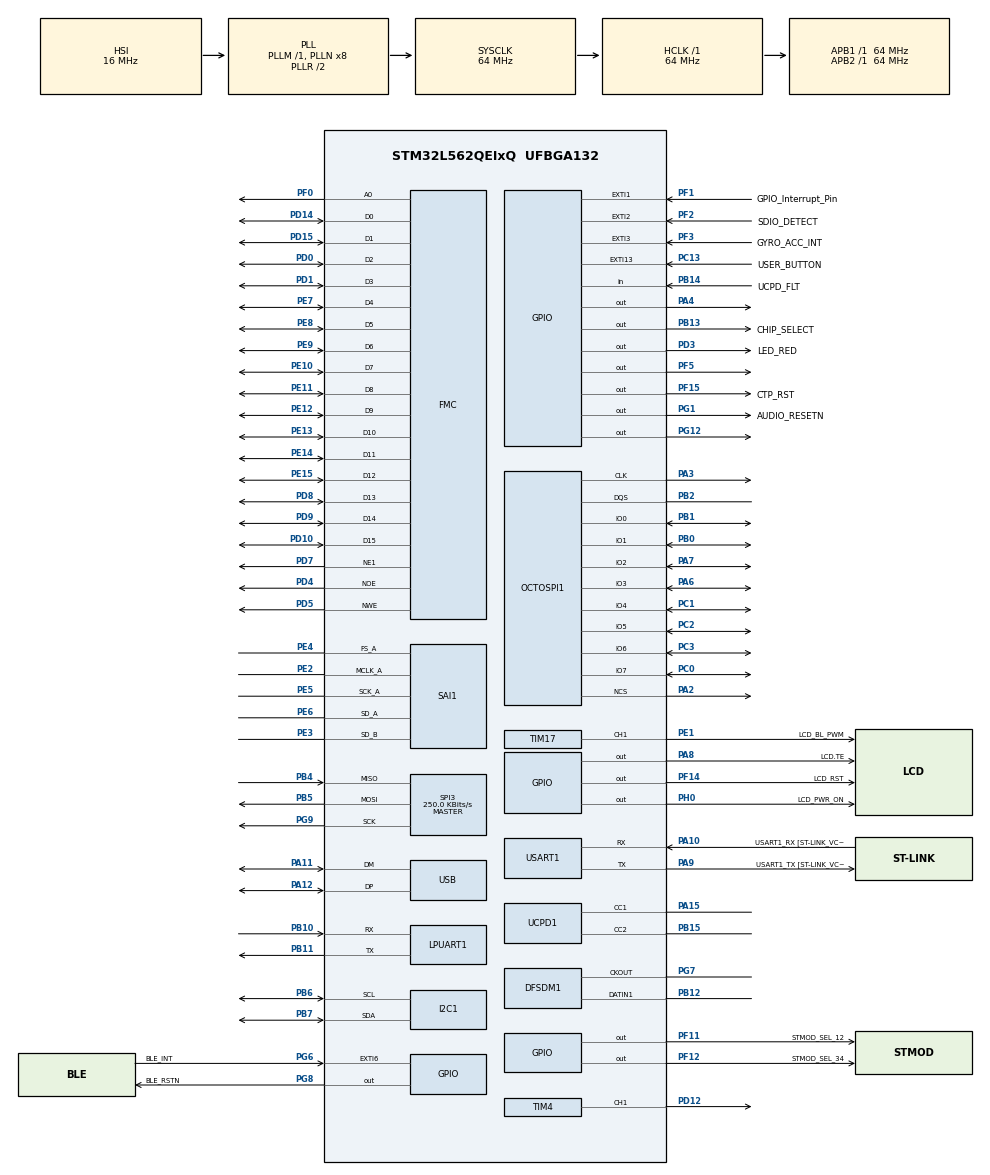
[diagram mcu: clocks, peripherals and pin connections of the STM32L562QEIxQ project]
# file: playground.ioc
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I2C1.Timing=0x10707DBC
Mcu.Family=STM32L5
Mcu.Name=STM32L562QEIxQ
Mcu.Package=UFBGA132
Mcu.TrustZone=disable
NVIC.EXTI13_IRQn=true\:0\:0\:false\:false\:true\:true\:true
NVIC.PriorityGroup=NVIC_PRIORITYGROUP_3
NVIC.TIM4_IRQn=true\:0\:0\:false\:false\:true\:true\:true
PA10.GPIO_Label=USART1_RX [ST-LINK_VCP_TX]
PA10.Mode=Asynchronous
PA10.Signal=USART1_RX
PA11.Mode=Device
PA11.Signal=USB_DM
PA12.Mode=Device
PA12.Signal=USB_DP
PA13\ (JTMS/SWDIO).Mode=Trace_Asynchronous_SW
PA13\ (JTMS/SWDIO).Signal=DEBUG_JTMS-SWDIO
PA14\ (JTCK/SWCLK).Mode=Trace_Asynchronous_SW
PA14\ (JTCK/SWCLK).Signal=DEBUG_JTCK-SWCLK
PA15\ (JTDI).Mode=Source_AllSignals
PA15\ (JTDI).Signal=UCPD1_CC1
PA2.Mode=octods_mode
PA2.Signal=OCTOSPI1_NCS
PA3.Mode=octods_mode
PA3.Signal=OCTOSPI1_CLK
PA4.Signal=GPIO_Output
PA6.Mode=octods_mode
PA6.Signal=OCTOSPI1_IO3
PA7.Mode=octods_mode
PA7.Signal=OCTOSPI1_IO2
PA8.GPIO_Label=LCD.TE
PA8.Signal=GPIO_Output
PA9.GPIO_Label=USART1_TX [ST-LINK_VCP_RX]
PA9.Mode=Asynchronous
PA9.Signal=USART1_TX
PB0.Mode=octods_mode
PB0.Signal=OCTOSPI1_IO1
PB1.Mode=octods_mode
PB1.Signal=OCTOSPI1_IO0
PB10.Mode=Asynchronous
PB10.Signal=LPUART1_RX
PB11.Mode=Asynchronous
PB11.Signal=LPUART1_TX
PB12.Signal=S_DATAIN1DFSDM1
PB13.GPIO_Label=CHIP_SELECT
PB13.Signal=GPIO_Output
PB14.GPIO_Label=UCPD_FLT
PB14.Signal=GPIO_Input
PB15.Mode=Source_AllSignals
PB15.Signal=UCPD1_CC2
PB2.Mode=octods_mode
PB2.Signal=OCTOSPI1_DQS
PB3\ (JTDO/TRACESWO).Mode=Trace_Asynchronous_SW
PB3\ (JTDO/TRACESWO).Signal=DEBUG_JTDO-SWO
PB4\ (NJTRST).Mode=Full_Duplex_Master
PB4\ (NJTRST).Signal=SPI3_MISO
PB5.Mode=Full_Duplex_Master
PB5.Signal=SPI3_MOSI
PB6.Mode=I2C
PB6.Signal=I2C1_SCL
PB7.Mode=I2C
PB7.Signal=I2C1_SDA
PC0.Mode=octods_mode
PC0.Signal=OCTOSPI1_IO7
PC1.Mode=octods_mode
PC1.Signal=OCTOSPI1_IO4
PC10.Signal=SDMMC1_D2
PC11.Signal=SDMMC1_D3
PC12.Signal=SDMMC1_CK
PC13.GPIO_Label=USER_BUTTON
PC13.Signal=GPXTI13
PC14-OSC32_IN\ (PC14).Mode=LSE-External-Oscillator
PC14-OSC32_IN\ (PC14).Signal=RCC_OSC32_IN
PC15-OSC32_OUT\ (PC15).Mode=LSE-External-Oscillator
PC15-OSC32_OUT\ (PC15).Signal=RCC_OSC32_OUT
PC2.Mode=octods_mode
PC2.Signal=OCTOSPI1_IO5
PC3.Mode=octods_mode
PC3.Signal=OCTOSPI1_IO6
PC8.Signal=SDMMC1_D0
PC9.Signal=SDMMC1_D1
PD0.Signal=FMC_D2_DA2
PD1.Signal=FMC_D3_DA3
PD10.Signal=FMC_D15_DA15
PD12.Signal=S_TIM4_CH1
PD14.Signal=FMC_D0_DA0
PD15.Signal=FMC_D1_DA1
PD2.Signal=SDMMC1_CMD
PD3.GPIO_Label=LED_RED
PD3.Signal=GPIO_Output
PD4.Signal=FMC_NOE
PD5.Signal=FMC_NWE
PD7.Mode=NorPsramChipSelect1_1
PD7.Signal=FMC_NE1
PD8.Signal=FMC_D13_DA13
PD9.Signal=FMC_D14_DA14
PE1.GPIO_Label=LCD_BL_PWM
PE1.Signal=S_TIM17_CH1
PE10.Signal=FMC_D7_DA7
PE11.Signal=FMC_D8_DA8
PE12.Signal=FMC_D9_DA9
PE13.Signal=FMC_D10_DA10
PE14.Signal=FMC_D11_DA11
PE15.Signal=FMC_D12_DA12
PE2.Mode=SAI_A_MasterWithClock
PE2.Signal=SAI1_MCLK_A
PE3.Mode=SAI_B_SPDIF
PE3.Signal=SAI1_SD_B
PE4.Mode=SAI_A_MasterWithClock
PE4.Signal=SAI1_FS_A
PE5.Mode=SAI_A_MasterWithClock
PE5.Signal=SAI1_SCK_A
PE6.Mode=SAI_A_MasterWithClock
PE6.Signal=SAI1_SD_A
PE7.Signal=FMC_D4_DA4
PE8.Signal=FMC_D5_DA5
PE9.Signal=FMC_D6_DA6
PF0.Signal=FMC_A0
PF1.GPIO_Label=GPIO_Interrupt_Pin
PF1.Signal=GPXTI1
PF11.GPIO_Label=STMOD_SEL_12
PF11.Signal=GPIO_Output
PF12.GPIO_Label=STMOD_SEL_34
PF12.Signal=GPIO_Output
PF14.GPIO_Label=LCD_RST
PF14.Signal=GPIO_Output
PF15.GPIO_Label=CTP_RST
PF15.Signal=GPIO_Output
PF2.GPIO_Label=SDIO_DETECT
PF2.Signal=GPXTI2
PF3.GPIO_Label=GYRO_ACC_INT
PF3.Signal=GPXTI3
PF5.Signal=GPIO_Output
PG1.GPIO_Label=AUDIO_RESETN
PG1.Signal=GPIO_Output
PG12.Signal=GPIO_Output
PG2.Signal=SPI1_SCK
PG3.Signal=SPI1_MISO
PG4.Signal=SPI1_MOSI
PG5.GPIO_Label=BLE_CSN
PG5.Signal=SPI1_NSS
PG6.GPIO_Label=BLE_INT
PG6.Signal=GPXTI6
PG7.Signal=S_CKOUTDFSDM1
PG8.GPIO_Label=BLE_RSTN
PG8.Signal=GPIO_Output
PG9.Mode=Full_Duplex_Master
PG9.Signal=SPI3_SCK
PH0-OSC_IN\ (PH0).GPIO_Label=LCD_PWR_ON
PH0-OSC_IN\ (PH0).Signal=GPIO_Output
ProjectManager.HeapSize=0x200
ProjectManager.StackSize=0x400
ProjectManager.TargetToolchain=STM32CubeIDE
RCC.ADCFreq_Value=96000000
RCC.AHBFreq_Value=64000000
RCC.APB1Freq_Value=64000000
RCC.APB1TimFreq_Value=64000000
RCC.APB2Freq_Value=64000000
RCC.APB2TimFreq_Value=64000000
RCC.CK48CLockSelection=RCC_USBCLKSOURCE_MSI
RCC.CortexFreq_Value=64000000
RCC.HCLKFreq_Value=64000000
RCC.HSE_VALUE=8000000
RCC.HSI48_VALUE=48000000
RCC.HSI_VALUE=16000000
RCC.MSIClockRange=RCC_MSIRANGE_11
RCC.MSI_VALUE=48000000
RCC.PLLSAI1M=4
RCC.PLLSAI1N=48
RCC.PLLSAI1P=RCC_PLLP_DIV17
RCC.PLLSAI1Source=RCC_PLLSAI1SOURCE_HSI
RCC.PLLSourceVirtual=RCC_PLLSOURCE_HSI
RCC.SDMMCClockSelection=RCC_SDIOCLKSOURCE_CLK48
RCC.SYSCLKFreq_VALUE=64000000
RCC.SYSCLKSource=RCC_SYSCLKSOURCE_PLLCLK
RCC.USBFreq_Value=48000000
RCC.VCOOutputFreq_Value=128000000
SAI1.ErrorAudioFreq-SAI_A_MasterWithClock=-77.02 %
SAI1.Instance-SAI_A_MasterWithClock=SAI$Index_Block_A
SAI1.Instance-SAI_B_SPDIF=SAI$Index_Block_B
SAI1.MckOutput-SAI_A_MasterWithClock=SAI_MCK_OUTPUT_ENABLE
SAI1.RealAudioFreq-SAI_A_MasterWithClock=44.117 KHz
SAI1.RealAudioFreq-SAI_B_SPDIF=214.285 KHz
SAI1.VirtualMode-SAI_A_MasterWithClock=VM_MASTER
SAI1.VirtualMode-SAI_B_SPDIF=VM_SPDIF
SH.FMC_A0.0=FMC_A0,A0_1
SH.FMC_D0_DA0.0=FMC_DA0
SH.FMC_D0_DA0.1=FMC_D0,16b-d1
SH.FMC_D10_DA10.0=FMC_DA10
SH.FMC_D10_DA10.1=FMC_D10,16b-d1
SH.FMC_D11_DA11.0=FMC_DA11
SH.FMC_D11_DA11.1=FMC_D11,16b-d1
SH.FMC_D12_DA12.0=FMC_DA12
SH.FMC_D12_DA12.1=FMC_D12,16b-d1
SH.FMC_D13_DA13.0=FMC_DA13
SH.FMC_D13_DA13.1=FMC_D13,16b-d1
SH.FMC_D14_DA14.0=FMC_DA14
SH.FMC_D14_DA14.1=FMC_D14,16b-d1
SH.FMC_D15_DA15.0=FMC_DA15
SH.FMC_D15_DA15.1=FMC_D15,16b-d1
SH.FMC_D1_DA1.0=FMC_DA1
SH.FMC_D1_DA1.1=FMC_D1,16b-d1
SH.FMC_D2_DA2.0=FMC_DA2
SH.FMC_D2_DA2.1=FMC_D2,16b-d1
SH.FMC_D3_DA3.0=FMC_DA3
SH.FMC_D3_DA3.1=FMC_D3,16b-d1
SH.FMC_D4_DA4.0=FMC_DA4
SH.FMC_D4_DA4.1=FMC_D4,16b-d1
SH.FMC_D5_DA5.0=FMC_DA5
SH.FMC_D5_DA5.1=FMC_D5,16b-d1
SH.FMC_D6_DA6.0=FMC_DA6
SH.FMC_D6_DA6.1=FMC_D6,16b-d1
SH.FMC_D7_DA7.0=FMC_DA7
SH.FMC_D7_DA7.1=FMC_D7,16b-d1
SH.FMC_D8_DA8.0=FMC_DA8
SH.FMC_D8_DA8.1=FMC_D8,16b-d1
SH.FMC_D9_DA9.0=FMC_DA9
SH.FMC_D9_DA9.1=FMC_D9,16b-d1
SH.FMC_NOE.0=FMC_NOE,Lcd1
SH.FMC_NWE.0=FMC_NWE,Lcd1
SH.S_CKOUTDFSDM1.0=DFSDM1_CKOUT,CKOUT
SH.S_DATAIN1DFSDM1.0=DFSDM1_DATIN1,Manchester_input_from_ch1
SH.S_TIM17_CH1.0=TIM17_CH1,PWM Generation1 CH1
SH.S_TIM4_CH1.0=TIM4_CH1,Output Compare1 CH1
SPI3.BaudRatePrescaler=SPI_BAUDRATEPRESCALER_256
SPI3.CalculateBaudRate=250.0 KBits/s
SPI3.DataSize=SPI_DATASIZE_8BIT
SPI3.Direction=SPI_DIRECTION_2LINES
SPI3.FirstBit=SPI_FIRSTBIT_MSB
SPI3.Mode=SPI_MODE_MASTER
SPI3.VirtualType=VM_MASTER
TIM17.Channel=TIM_CHANNEL_1
TIM4.AutoReloadPreload=TIM_AUTORELOAD_PRELOAD_DISABLE
TIM4.Channel-Output\ Compare1\ CH1=TIM_CHANNEL_1
TIM4.OCMode_1=TIM_OCMODE_TOGGLE
TIM4.Period=9999
TIM4.Prescaler=6399
USART1.VirtualMode-Asynchronous=VM_ASYNC
VP_DFSDM1_VS_IN0.Mode=Parallel_Input_ch0
VP_DFSDM1_VS_IN2.Mode=Parallel_Input_ch2
VP_PWR_VS_DBSignals.Mode=DisableDeadBatterySignals
VP_TIM16_VS_ClockSourceINT.Mode=Enable_Timer
VP_TIM17_VS_ClockSourceINT.Mode=Enable_Timer
VP_TIM4_VS_ClockSourceINT.Mode=Internal
board=STM32L562E-DK

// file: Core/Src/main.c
/* USER CODE BEGIN Header */
/**
  ******************************************************************************
  * @file           : main.c
  * @brief          : Main program body
  ******************************************************************************
  * @attention
  *
  * <h2><center>&copy; Copyright (c) 2022 STMicroelectronics.
  * All rights reserved.</center></h2>
  *
  * This software component is licensed by ST under BSD 3-Clause license,
  * the "License"; You may not use this file except in compliance with the
  * License. You may obtain a copy of the License at:
  *                        opensource.org/licenses/BSD-3-Clause
  *
  ******************************************************************************
  */
/* USER CODE END Header */
#include "main.h"
#include "dfsdm.h"
#include "i2c.h"
#include "usart.h"
#include "octospi.h"
#include "sai.h"
#include "spi.h"
#include "tim.h"
#include "ucpd.h"
#include "usb.h"
#include "gpio.h"
#include "fmc.h"

/* USER CODE BEGIN Includes */
#include "lib_radio.h"
/* USER CODE END Includes */

/* USER CODE BEGIN PD */
#define INT_ARRAY_SIZE                          16u
#define TEST_MSG_ARRAY_SIZE                     18u
#define TEST_MSG_TO_SEND                        {0x11, 0xF4, 0xF3, 0xF2, 0xF1, 0x34, 0x33, 0x32, 0x31, 0x80, 0x07, 0xC5, 0xC5, 0xC5, 0xC5, 0xC5, 0xC5, 0xC5}
/* USER CODE END PD */

/* USER CODE BEGIN PV */
uint8_t* IntArrayPtr;
uint8_t IntArray[INT_ARRAY_SIZE];
/* USER CODE END PV */

void SystemClock_Config(void);
void PeriphCommonClock_Config(void);

int main(void)
{

  /* MCU Configuration--------------------------------------------------------*/

  /* Reset of all peripherals, Initializes the Flash interface and the Systick. */
  HAL_Init();

  /* Configure the system clock */
  SystemClock_Config();

/* Configure the peripherals common clocks */
  PeriphCommonClock_Config();

  /* Initialize all configured peripherals */
  MX_GPIO_Init();
  MX_DFSDM1_Init();
  MX_FMC_Init();
  MX_I2C1_Init();
  MX_LPUART1_UART_Init();
  MX_USART1_UART_Init();
  MX_OCTOSPI1_Init();
  MX_SAI1_Init();
  MX_TIM4_Init();
  MX_TIM16_Init();
  MX_TIM17_Init();
  MX_UCPD1_Init();
  MX_USB_PCD_Init();
  MX_SPI3_Init();
  /* USER CODE BEGIN 2 */
  uint8_t TestArrayMessage[TEST_MSG_ARRAY_SIZE] = TEST_MSG_TO_SEND;

  HAL_GPIO_WritePin(STMOD_SEL_12_GPIO_Port, STMOD_SEL_12_Pin, GPIO_PIN_RESET); /* Set SEL pin states to initiate SPI3 on CN4 */
  HAL_GPIO_WritePin(STMOD_SEL_34_GPIO_Port, STMOD_SEL_34_Pin, GPIO_PIN_RESET);

  sendConfigurationSettings(&hspi3, CHIP_SELECT_GPIO_Port, CHIP_SELECT_Pin);
  sendMessage(TestArrayMessage, TEST_MSG_ARRAY_SIZE);
  getRadioIntStatus(IntArray);
  /* USER CODE END 2 */

  /* Infinite loop */
   while (1)
  {

  }
}

void SystemClock_Config(void)
{
  RCC_OscInitTypeDef RCC_OscInitStruct = {0};
  RCC_ClkInitTypeDef RCC_ClkInitStruct = {0};

  /** Configure the main internal regulator output voltage
  */
  if (HAL_PWREx_ControlVoltageScaling(PWR_REGULATOR_VOLTAGE_SCALE1) != HAL_OK)
  {
    Error_Handler();
  }
  /** Configure LSE Drive Capability
  */
  HAL_PWR_EnableBkUpAccess();
  __HAL_RCC_LSEDRIVE_CONFIG(RCC_LSEDRIVE_LOW);
  /** Initializes the RCC Oscillators according to the specified parameters
  * in the RCC_OscInitTypeDef structure.
  */
  RCC_OscInitStruct.OscillatorType = RCC_OSCILLATORTYPE_HSI|RCC_OSCILLATORTYPE_LSE
                              |RCC_OSCILLATORTYPE_MSI;
  RCC_OscInitStruct.LSEState = RCC_LSE_ON;
  RCC_OscInitStruct.HSIState = RCC_HSI_ON;
  RCC_OscInitStruct.HSICalibrationValue = RCC_HSICALIBRATION_DEFAULT;
  RCC_OscInitStruct.MSIState = RCC_MSI_ON;
  RCC_OscInitStruct.MSICalibrationValue = RCC_MSICALIBRATION_DEFAULT;
  RCC_OscInitStruct.MSIClockRange = RCC_MSIRANGE_11;
  RCC_OscInitStruct.PLL.PLLState = RCC_PLL_ON;
  RCC_OscInitStruct.PLL.PLLSource = RCC_PLLSOURCE_HSI;
  RCC_OscInitStruct.PLL.PLLM = 1;
  RCC_OscInitStruct.PLL.PLLN = 8;
  RCC_OscInitStruct.PLL.PLLP = RCC_PLLP_DIV7;
  RCC_OscInitStruct.PLL.PLLQ = RCC_PLLQ_DIV2;
  RCC_OscInitStruct.PLL.PLLR = RCC_PLLR_DIV2;
  if (HAL_RCC_OscConfig(&RCC_OscInitStruct) != HAL_OK)
  {
    Error_Handler();
  }
  /** Initializes the CPU, AHB and APB buses clocks
  */
  RCC_ClkInitStruct.ClockType = RCC_CLOCKTYPE_HCLK|RCC_CLOCKTYPE_SYSCLK
                              |RCC_CLOCKTYPE_PCLK1|RCC_CLOCKTYPE_PCLK2;
  RCC_ClkInitStruct.SYSCLKSource = RCC_SYSCLKSOURCE_PLLCLK;
  RCC_ClkInitStruct.AHBCLKDivider = RCC_SYSCLK_DIV1;
  RCC_ClkInitStruct.APB1CLKDivider = RCC_HCLK_DIV1;
  RCC_ClkInitStruct.APB2CLKDivider = RCC_HCLK_DIV1;

  if (HAL_RCC_ClockConfig(&RCC_ClkInitStruct, FLASH_LATENCY_3) != HAL_OK)
  {
    Error_Handler();
  }
  /** Enable MSI Auto calibration
  */
  HAL_RCCEx_EnableMSIPLLMode();
}

void PeriphCommonClock_Config(void)
{
  RCC_PeriphCLKInitTypeDef PeriphClkInit = {0};

  /** Initializes the common periph clock
  */
  PeriphClkInit.PeriphClockSelection = RCC_PERIPHCLK_SAI1;
  PeriphClkInit.Sai1ClockSelection = RCC_SAI1CLKSOURCE_PLLSAI1;
  PeriphClkInit.PLLSAI1.PLLSAI1Source = RCC_PLLSAI1SOURCE_HSI;
  PeriphClkInit.PLLSAI1.PLLSAI1M = 4;
  PeriphClkInit.PLLSAI1.PLLSAI1N = 48;
  PeriphClkInit.PLLSAI1.PLLSAI1P = RCC_PLLP_DIV17;
  PeriphClkInit.PLLSAI1.PLLSAI1Q = RCC_PLLQ_DIV2;
  PeriphClkInit.PLLSAI1.PLLSAI1R = RCC_PLLR_DIV2;
  PeriphClkInit.PLLSAI1.PLLSAI1ClockOut = RCC_PLLSAI1_SAI1CLK;
  if (HAL_RCCEx_PeriphCLKConfig(&PeriphClkInit) != HAL_OK)
  {
    Error_Handler();
  }
}

void Error_Handler(void)
{
  __disable_irq();
  while (1)
  {
  }
}

/************************ (C) COPYRIGHT STMicroelectronics *****END OF FILE****/
